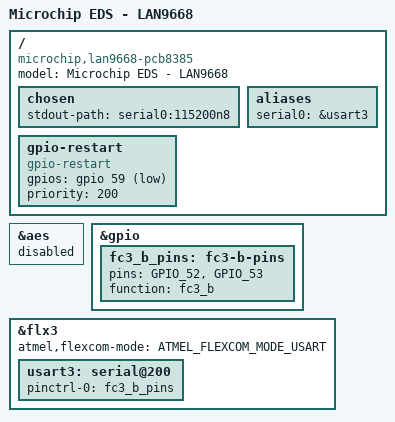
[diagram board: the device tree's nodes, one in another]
// SPDX-License-Identifier: (GPL-2.0+ OR MIT)
/*
 * lan966x-pcb8385.dts - Device Tree file for LAN966X-PCB8385 board
 *
 * Copyright (C) 2022 Microchip Technology Inc. and its subsidiaries
 *
 * Author: Horatiu Vultur <horatiu.vultur@microchip.com>
 */
/dts-v1/;

#include "lan966x.dtsi"
#include "dt-bindings/phy/phy-lan966x-serdes.h"

/ {
	model = "Microchip EDS - LAN9668";
	compatible = "microchip,lan9668-pcb8385", "microchip,lan9668", "microchip,lan966";

	chosen {
		stdout-path = "serial0:115200n8";
	};

	aliases {
		serial0 = &usart3;
	};

	gpio-restart {
		compatible = "gpio-restart";
		gpios = <&gpio 59 GPIO_ACTIVE_LOW>;
		priority = <200>;
	};
};

&aes {
	status = "disabled"; /* Reserved by secure OS */
};

&gpio {
	fc3_b_pins: fc3-b-pins {
		/* RX, TX */
		pins = "GPIO_52", "GPIO_53";
		function = "fc3_b";
	};
};

&flx3 {
	atmel,flexcom-mode = <ATMEL_FLEXCOM_MODE_USART>;
	status = "okay";

	usart3: serial@200 {
		pinctrl-0 = <&fc3_b_pins>;
		pinctrl-names = "default";
		status = "okay";
	};
};
